# M3H4 register map
File version: 0.1
TOSHIBA Cortex-M3 MCU
Registers are 32-bit, read-write, reset 0x0 unless marked. A register's access mark holds for its fields unless they carry their own. Offsets are from the block's base; lines under a group give offsets from that group; [hi:lo] are bit positions; {n}, {i} and the like mark numbered series; 'fields as' and 'values as' point back to an identical list; <NAME> marks a mode.

## Memory map
0x4003E000 IA blocks up to offset 0x32 — Interrupt control A Register
0x4003E400 RLM blocks up to offset 0x10 — Reset LOSC_Low power_ Management register
0x4003E800 I2CS size 0x4 — I2C Wakeup control register
0x4003EC00 LVD size 0x1 — LVD0
0x4004C000 DMA blocks up to offset 0x50 — DMA Controller
0x40054000 DA size 0x8 — Digital analog converter (DAC)
0x40098000 TSPI0 blocks up to offset 0x208 — Serial Interface (TSPI)
0x40099000 TSPI1 blocks up to offset 0x208
0x400A0000 I2C0 size 0x28 — I2C
0x400A1000 I2C1 size 0x28
0x400A2000 I2C2 size 0x28
0x400B8800 AD blocks up to offset 0x1A0 — ADC
0x400BA000 T32A0 blocks up to offset 0xFC — T32A
0x400BA100 T32A1 blocks up to offset 0xFC
0x400BA200 T32A2 blocks up to offset 0xFC
0x400BA300 T32A3 blocks up to offset 0xFC
0x400BA400 T32A4 blocks up to offset 0xFC
0x400BA500 T32A5 blocks up to offset 0xFC
0x400BB000 UART0 size 0x28 — UART
0x400BB100 UART1 size 0x28
0x400BB200 UART2 size 0x28
0x400BB400 SIWD size 0x18
0x400BB600 DNF size 0x8
0x400BB800 TSEL size 0x2C — TRGSEL
0x400C0000 PA blocks up to offset 0x3C — Port A
0x400C0100 PB blocks up to offset 0x3C — Port B
0x400C0200 PC blocks up to offset 0x3C — Port C
0x400C0300 PD blocks up to offset 0x3C — Port D
0x400C0400 PE blocks up to offset 0x3C — Port E
0x400C0600 PG blocks up to offset 0x3C
0x400C0700 PH blocks up to offset 0x3C
0x400C0800 PJ blocks up to offset 0x3C
0x400C0900 PK blocks up to offset 0x3C
0x400C0A00 PL blocks up to offset 0x3C
0x400C0B00 PM blocks up to offset 0x3C
0x400C0C00 PN blocks up to offset 0x3C
0x400CC000 RTC blocks up to offset 0x11
0x400E7000 RMC size 0x38
0x400F1000 OFD size 0x24
0x400F3000 CG blocks up to offset 0x60
0x400F3200 TRM size 0x10
0x400F4E00 IB blocks up to offset 0x8F — Interrupt control register B
0x400F4F00 IMN blocks up to offset 0x14
0x400F6000 PMD blocks up to offset 0x68
0x400F7000 EN size 0x34 — Encoder Input (ENC)
0x5DFF0000 FC blocks up to offset 0x15C

## IA — Interrupt control A Register
Base 0x4003E000
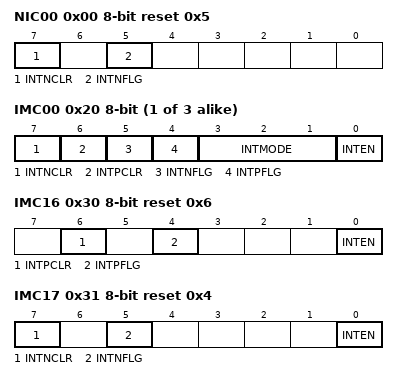
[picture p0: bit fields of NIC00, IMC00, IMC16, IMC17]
0x00 NIC00 8-bit reset 0x5 — Non makeable Interrupt Control(A) 00
  [7] INTNCLR wo, [5] INTNFLG ro
{0x20+i} IMC{i:02} 8-bit (i=0..2) — Interrupu Mode Control Register(A) {i:02}
  [7] INTNCLR wo, [6] INTPCLR wo, [5] INTNFLG ro, [4] INTPFLG ro, [3:1] INTMODE, [0] INTEN
0x30 IMC16 8-bit reset 0x6 — Interrupu Mode Control Register(A) 16
  [6] INTPCLR wo, [4] INTPFLG ro, [0] INTEN
0x31 IMC17 8-bit reset 0x4 — Interrupu Mode Control Register(A) 17
  [7] INTNCLR wo, [5] INTNFLG ro, [0] INTEN

## RLM — Reset LOSC_Low power_ Management register
Base 0x4003E400
0x00 LOSCCR 8-bit — Low OSC Control Register
  [0] XTEN
0x01 SHTDNOP 8-bit — Power Shut Down Control Register
  [0] PTKEEP
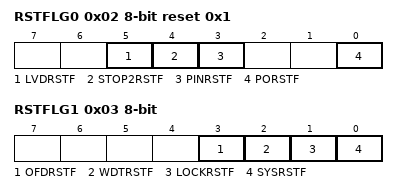
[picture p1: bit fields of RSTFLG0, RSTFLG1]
0x02 RSTFLG0 8-bit reset 0x1 (reset mask 0x1) — Reset flag register 0
  [5] LVDRSTF, [4] STOP2RSTF, [3] PINRSTF, [0] PORSTF
0x03 RSTFLG1 8-bit — Reset flag register 1
  [3] OFDRSTF, [2] WDTRSTF, [1] LOCKRSTF, [0] SYSRSTF
0x0F PROTECT 8-bit reset 0xC1

## I2CS — I2C Wakeup control register
Base 0x4003E800
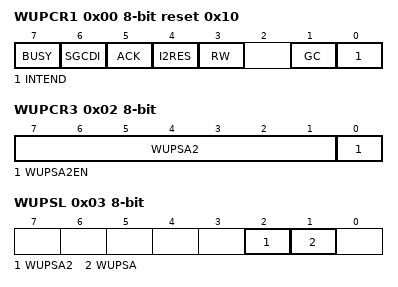
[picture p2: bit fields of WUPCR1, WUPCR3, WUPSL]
0x00 WUPCR1 8-bit reset 0x10 — I2C Wakeup control register1
  [7] BUSY ro, [6] SGCDI, [5] ACK, [4] I2RES, [3] RW ro, [1] GC ro, [0] INTEND
0x01 WUPCR2 8-bit — I2C Wakeup control register2
  [7:1] WUPSA1
0x02 WUPCR3 8-bit — I2C Wakeup control register3
  [7:1] WUPSA2, [0] WUPSA2EN
0x03 WUPSL 8-bit ro — I2C Wakeup Status register
  [2] WUPSA2, [1] WUPSA

## LVD — LVD0
Base 0x4003EC00
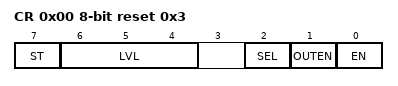
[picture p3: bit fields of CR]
0x00 CR 8-bit reset 0x3 — LVD Control register
  [7] ST ro, [6:4] LVL, [2] SEL, [1] OUTEN, [0] EN

## DMA — DMA Controller
Base 0x4004C000
0x00 STATUS ro reset 0x101F0000 — DMA Status Register
  [0] MASTER_ENABLE
0x04 CFG wo reset 0xFFFFFFFFFFFFFFFF — DMA Configuration Register
  [0] MASTER_ENABLE
0x08 CTRLBASEPTR — DMA Control Data Base Pointer Register
  [31:10] CTRL_BASE_PTR
0x0C ALTCTRLBASEPTR ro — DMA Channel Alternate Control Data Base Pointer Register
  [31:0] ALT_CTRL_BASE_PTR
0x14 CHNLSWREQUEST wo — DMA Channel Software Request Register
  [31:0] CHNL_SW_REQUEST
0x18 CHNLUSEBURSTSET — DMA Channel Useburst Set Register
  [31:0] CHNL_USEBURST_SET
0x1C CHNLUSEBURSTCLR wo — DMA Channel Useburst Clear Register
  [31:0] CHNL_USEBURST_CLR
0x20 CHNLREQMASKSET — DMA Channel Request Mask Set Register
  [31:0] CHNL_REQ_MASK_SET
0x24 CHNLREQMASKCLR wo — DMA Channel Request Mask Clear Register
  [31:0] CHNL_REQ_MASK_CLR
0x28 CHNLENABLESET — DMA Channel Enable Set Register
  [31:0] CHNL_ENABLE_SET
0x2C CHNLENABLECLR wo — DMA Channel Enable Clear Register
  [31:0] CHNL_ENABLE_CLR
0x30 CHNLPRIALTSET — DMA Channel Primary-Alternate Set Register
  [31:0] CHNL_PRI_ALT_SET
0x34 CHNLPRIALTCLR wo — DMA Channel Primary-Alternate Clear Register
  [31:0] CHNL_PRI_ALT_CLR
0x38 CHNLPRIORITYSET — DMA Channel Priority Set Register
  [31:0] CHNL_PRIORITY_SET
0x3C CHNLPRIORITYCLR wo — DMA Channel Priority Clear Register
  [31:0] CHNL_PRIORITY_CLR
0x4C ERRCLR — DMA Bus Error Clear Register
  [0] ERR_CLR
